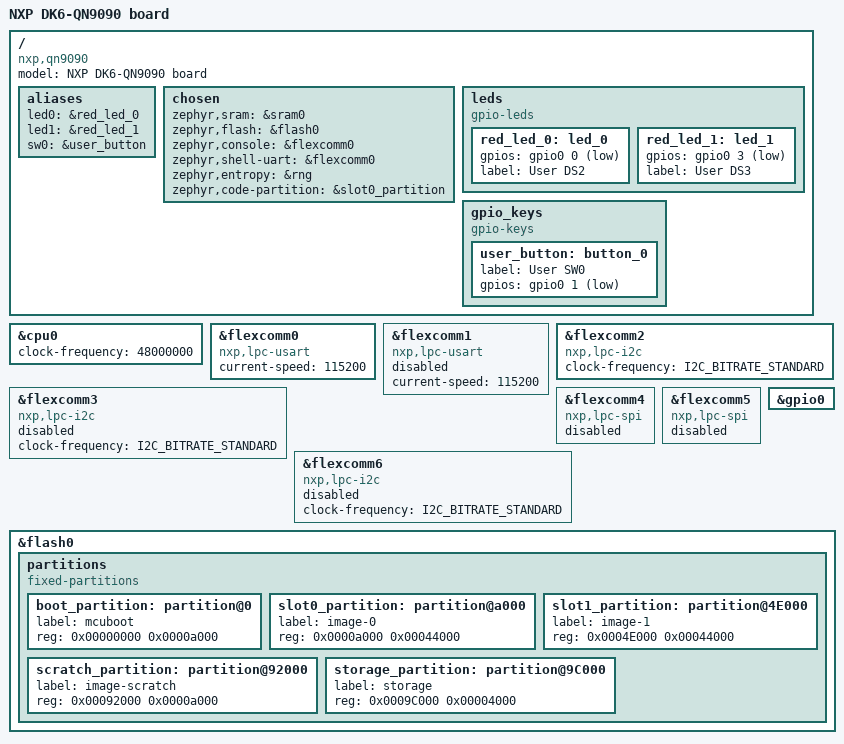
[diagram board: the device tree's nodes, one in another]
/*
 * Copyright (c) 2021, Vincent van der Locht
 * Copyright (c) 2022, Hessel van der Molen, sendrato.com
 *
 * SPDX-License-Identifier: Apache-2.0
 */

/dts-v1/;

#include <nxp/nxp_qn9090.dtsi>

/ {
	model = "NXP DK6-QN9090 board";
    compatible = "nxp,qn9090", "nxp,k32";

	aliases {
		led0 = &red_led_0;
		led1 = &red_led_1;
		sw0 = &user_button;
	};

	chosen {
		zephyr,sram = &sram0;
		zephyr,flash = &flash0;
		zephyr,console = &flexcomm0;
		zephyr,shell-uart = &flexcomm0;
        zephyr,entropy = &rng;
        zephyr,code-partition = &slot0_partition;
    };

	leds {
		compatible = "gpio-leds";
		red_led_0: led_0 {
			gpios = <&gpio0 0 GPIO_ACTIVE_LOW>;
			label = "User DS2";
		};
		red_led_1: led_1 {
			gpios = <&gpio0 3 GPIO_ACTIVE_LOW>;
			label = "User DS3";
		};
	};

	gpio_keys {
		compatible = "gpio-keys";
		user_button: button_0 {
			label = "User SW0";
			gpios = <&gpio0 1 GPIO_ACTIVE_LOW>;
		};
	};

};

&cpu0 {
	clock-frequency = <48000000>;
};


&flexcomm0 {
    compatible = "nxp,lpc-usart";
    current-speed = <115200>;
	status = "okay";
};

&flexcomm1 {
    compatible = "nxp,lpc-usart";
	current-speed = <115200>;
	status = "disabled";
};

&flexcomm2 {
    compatible = "nxp,lpc-i2c";
    clock-frequency = <I2C_BITRATE_STANDARD>;
	#address-cells = <1>;
	#size-cells = <0>;
	status = "okay";
};

&flexcomm3 {
    compatible = "nxp,lpc-i2c";
    clock-frequency = <I2C_BITRATE_STANDARD>;
	#address-cells = <1>;
	#size-cells = <0>;
    status = "disabled";
};

&flexcomm4 {
    compatible = "nxp,lpc-spi";
	#address-cells = <1>;
	#size-cells = <0>;
    status = "disabled";
};

&flexcomm5 {
    compatible = "nxp,lpc-spi";
    #address-cells = <1>;
	#size-cells = <0>;
    status = "disabled";
};

&flexcomm6 {
    compatible = "nxp,lpc-i2c";
    clock-frequency = <I2C_BITRATE_STANDARD>;
    #address-cells = <1>;
    #size-cells = <0>;
    status = "disabled";
};

&gpio0 {
	status = "okay";
};

&flash0 {
  partitions {
    compatible = "fixed-partitions";
    #address-cells = <1>;
    #size-cells = <1>;

    boot_partition: partition@0 {
      label = "mcuboot";
      reg = <0x00000000 0x0000a000>;
    };
    slot0_partition: partition@a000 {
      label = "image-0";
      reg = <0x0000a000 0x00044000>;
    };
    slot1_partition: partition@4E000 {
      label = "image-1";
      reg = <0x0004E000 0x00044000>;
    };
    scratch_partition: partition@92000 {
      label = "image-scratch";
      reg = <0x00092000 0x0000a000>;
    };
    storage_partition: partition@9C000 {
      label = "storage";
      reg = <0x0009C000 0x00004000>;
    };
  };
};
